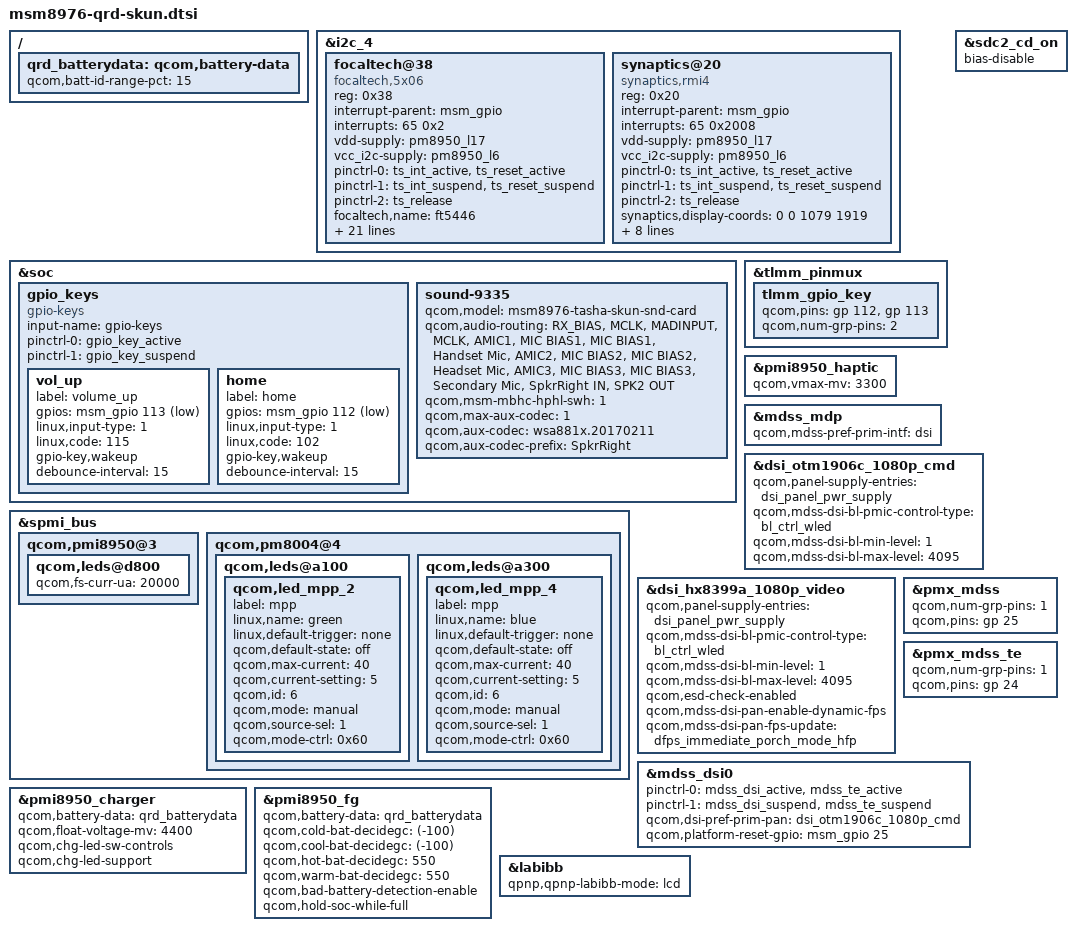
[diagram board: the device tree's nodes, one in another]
/*
 * Copyright (c) 2015, The Linux Foundation. All rights reserved.
 *
 * This program is free software; you can redistribute it and/or modify
 * it under the terms of the GNU General Public License version 2 and
 * only version 2 as published by the Free Software Foundation.
 *
 * This program is distributed in the hope that it will be useful,
 * but WITHOUT ANY WARRANTY; without even the implied warranty of
 * MERCHANTABILITY or FITNESS FOR A PARTICULAR PURPOSE.  See the
 * GNU General Public License for more details.
 */

#include "msm8976-qrd.dtsi"
#include "msm8976-wsa881x.dtsi"

&i2c_4 { /* BLSP1 QUP4 */
	focaltech@38 {
		compatible = "focaltech,5x06";
		reg = <0x38>;
		interrupt-parent = <&msm_gpio>;
		interrupts = <65 0x2>;
		vdd-supply = <&pm8950_l17>;
		vcc_i2c-supply = <&pm8950_l6>;
		/* pins used by touchscreen */
		pinctrl-names = "pmx_ts_active","pmx_ts_suspend","pmx_ts_release";
		pinctrl-0 = <&ts_int_active &ts_reset_active>;
		pinctrl-1 = <&ts_int_suspend &ts_reset_suspend>;
		pinctrl-2 = <&ts_release>;
		focaltech,name = "ft5446";
		focaltech,family-id = <0x06>;
		focaltech,reset-gpio = <&msm_gpio 64 0x0>;
		focaltech,irq-gpio = <&msm_gpio 65 0x2008>;
		focaltech,display-coords = <0 0 1079 1919>;
		focaltech,panel-coords = <0 0 1079 2084>;
		focaltech,button-map= <139 102 158>;
		focaltech,no-force-update;
		focaltech,i2c-pull-up;
		focaltech,group-id = <1>;
		focaltech,hard-reset-delay-ms = <20>;
		focaltech,soft-reset-delay-ms = <200>;
		focaltech,num-max-touches = <5>;
		focaltech,fw-delay-aa-ms = <30>;
		focaltech,fw-delay-55-ms = <30>;
		focaltech,fw-upgrade-id1 = <0x79>;
		focaltech,fw-upgrade-id2 = <0x08>;
		focaltech,fw-delay-readid-ms = <10>;
		focaltech,fw-delay-era-flsh-ms = <2000>;
		focaltech,fw-auto-cal;
		focaltech,ignore-id-check;
		focaltech,resume-in-workqueue;
	};

	synaptics@20 {
		compatible = "synaptics,rmi4";
		reg = <0x20>;
		interrupt-parent = <&msm_gpio>;
		interrupts = <65 0x2008>;
		vdd-supply = <&pm8950_l17>;
		vcc_i2c-supply = <&pm8950_l6>;
		/* pins used by touchscreen */
		pinctrl-names = "pmx_ts_active","pmx_ts_suspend","pmx_ts_release";
		pinctrl-0 = <&ts_int_active &ts_reset_active>;
		pinctrl-1 = <&ts_int_suspend &ts_reset_suspend>;
		pinctrl-2 = <&ts_release>;
		synaptics,display-coords = <0 0 1079 1919>;
		synaptics,panel-coords = <0 0 1079 2084>;
		synaptics,irq-gpio = <&msm_gpio 65 0x2008>;
		synaptics,reset-gpio = <&msm_gpio 64 0x0>;
		synaptics,i2c-pull-up;
		synaptics,power-down;
		synaptics,disable-gpios;
		synaptics,bypass-packrat-id-check;
		synaptics,button-map = <139 172 158>;
	};
};

&soc {
	gpio_keys {
		compatible = "gpio-keys";
		input-name = "gpio-keys";
		pinctrl-names = "tlmm_gpio_key_active","tlmm_gpio_key_suspend";
		pinctrl-0 = <&gpio_key_active>;
		pinctrl-1 = <&gpio_key_suspend>;

		vol_up {
			label = "volume_up";
			gpios = <&msm_gpio 113 0x1>;
			linux,input-type = <1>;
			linux,code = <115>;
			gpio-key,wakeup;
			debounce-interval = <15>;
		};

		home {
			label = "home";
			gpios = <&msm_gpio 112 0x1>;
			linux,input-type = <1>;
			linux,code = <102>;
			gpio-key,wakeup;
			debounce-interval = <15>;
		};
	};

	sound-9335 {
		qcom,model = "msm8976-tasha-skun-snd-card";

		qcom,audio-routing =
			"RX_BIAS", "MCLK",
			"MADINPUT", "MCLK",
			"AMIC1", "MIC BIAS1",
			"MIC BIAS1", "Handset Mic",
			"AMIC2", "MIC BIAS2",
			"MIC BIAS2", "Headset Mic",
			"AMIC3", "MIC BIAS3",
			"MIC BIAS3", "Secondary Mic",
			"SpkrRight IN", "SPK2 OUT";

		qcom,msm-mbhc-hphl-swh = <1>;
		qcom,max-aux-codec = <1>;
		qcom,aux-codec = "wsa881x.20170211";
		qcom,aux-codec-prefix = "SpkrRight";
	};
};

&tlmm_pinmux {
	tlmm_gpio_key {
		qcom,pins = <&gp 112>, <&gp 113>;
		qcom,num-grp-pins = <2>;
	};
};

&spmi_bus {
        qcom,pmi8950@3 {
                qcom,leds@d800 {
                        qcom,fs-curr-ua = <20000>;
                };
        };

	qcom,pm8004@4 {
		qcom,leds@a100 {
			status = "okay";
			qcom,led_mpp_2 {
				label = "mpp";
				linux,name = "green";
				linux,default-trigger = "none";
				qcom,default-state = "off";
				qcom,max-current = <40>;
				qcom,current-setting = <5>;
				qcom,id = <6>;
				qcom,mode = "manual";
				qcom,source-sel = <1>;
				qcom,mode-ctrl = <0x60>;
			};
		};

		qcom,leds@a300 {
			status = "okay";
			qcom,led_mpp_4 {
				label = "mpp";
				linux,name = "blue";
				linux,default-trigger = "none";
				qcom,default-state = "off";
				qcom,max-current = <40>;
				qcom,current-setting = <5>;
				qcom,id = <6>;
				qcom,mode = "manual";
				qcom,source-sel = <1>;
				qcom,mode-ctrl = <0x60>;
			};
		};
	};
};

&sdc2_cd_on {
	/delete-property/ bias-pull-up;
	bias-disable;
};

&pmi8950_haptic {
	qcom,vmax-mv = <3300>;
};

&mdss_mdp {
	qcom,mdss-pref-prim-intf = "dsi";
};

&dsi_otm1906c_1080p_cmd {
	qcom,panel-supply-entries = <&dsi_panel_pwr_supply>;
	qcom,mdss-dsi-bl-pmic-control-type = "bl_ctrl_wled";
	qcom,mdss-dsi-bl-min-level = <1>;
	qcom,mdss-dsi-bl-max-level = <4095>;
};

&dsi_hx8399a_1080p_video {
	qcom,panel-supply-entries = <&dsi_panel_pwr_supply>;
	qcom,mdss-dsi-bl-pmic-control-type = "bl_ctrl_wled";
	qcom,mdss-dsi-bl-min-level = <1>;
	qcom,mdss-dsi-bl-max-level = <4095>;
	qcom,esd-check-enabled;
	qcom,mdss-dsi-pan-enable-dynamic-fps;
	qcom,mdss-dsi-pan-fps-update = "dfps_immediate_porch_mode_hfp";
};

&pmx_mdss {
	qcom,num-grp-pins = <1>;
	qcom,pins = <&gp 25>;
};

&pmx_mdss_te {
	qcom,num-grp-pins = <1>;
	qcom,pins = <&gp 24>;
};

&mdss_dsi0 {
	pinctrl-names = "mdss_default", "mdss_sleep";
	pinctrl-0 = <&mdss_dsi_active &mdss_te_active>;
	pinctrl-1 = <&mdss_dsi_suspend &mdss_te_suspend>;
	qcom,dsi-pref-prim-pan = <&dsi_otm1906c_1080p_cmd>;

	qcom,platform-reset-gpio = <&msm_gpio 25 0>;
};

/ {
	qrd_batterydata: qcom,battery-data {
		qcom,batt-id-range-pct = <15>;
		#include "batterydata-qrd-skum-4v4-2920mah.dtsi"
	};
};

&pmi8950_charger {
	qcom,battery-data = <&qrd_batterydata>;
	qcom,float-voltage-mv = <4400>;
	qcom,chg-led-sw-controls;
	qcom,chg-led-support;
	status = "okay";
};

&pmi8950_fg {
	qcom,battery-data = <&qrd_batterydata>;
	qcom,cold-bat-decidegc = <(-100)>;
	qcom,cool-bat-decidegc = <(-100)>;
	qcom,hot-bat-decidegc = <550>;
	qcom,warm-bat-decidegc = <550>;
	qcom,bad-battery-detection-enable;
	qcom,hold-soc-while-full;
};

&labibb {
	status = "ok";
	qpnp,qpnp-labibb-mode = "lcd";
};
